VERSION ""

NS_ :

BS_:

BU_: CANOE_GW TARGET_IVI

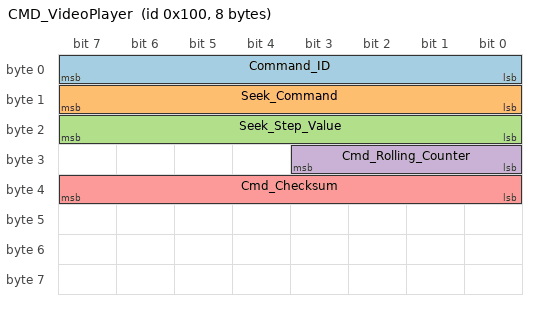
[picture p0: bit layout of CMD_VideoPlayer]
BO_ 256 CMD_VideoPlayer: 8 CANOE_GW
 SG_ Command_ID : 0|8@1+ (1,0) [0|4] "" TARGET_IVI
 SG_ Seek_Command : 8|8@1+ (1,0) [0|6] "" TARGET_IVI
 SG_ Seek_Step_Value : 16|8@1+ (1,0) [0|60] "s" TARGET_IVI
 SG_ Cmd_Rolling_Counter : 24|4@1+ (1,0) [0|15] "" TARGET_IVI
 SG_ Cmd_Checksum : 32|8@1+ (1,0) [0|255] "" TARGET_IVI

BO_ 257 STAT_VideoPlayer: 8 TARGET_IVI
 SG_ Playback_State : 0|8@1+ (1,0) [0|3] "" CANOE_GW
 SG_ Current_Track_Index : 8|8@1+ (1,0) [0|255] "" CANOE_GW
 SG_ Current_Play_Time : 16|16@0+ (1,0) [0|65535] "s" CANOE_GW
 SG_ Total_Duration : 32|16@0+ (1,0) [0|65535] "s" CANOE_GW
 SG_ System_Health_Status : 48|8@1+ (1,0) [0|255] "" CANOE_GW
 SG_ Status_Alive_Counter : 56|8@1+ (1,0) [0|255] "" CANOE_GW

VAL_ 256 Command_ID 0 "Idle" 1 "Play" 2 "Pause" 3 "Next" 4 "Previous" ;
VAL_ 256 Seek_Command 0 "None" 5 "Fast_Forward" 6 "Fast_Backward" ;
VAL_ 257 Playback_State 0 "Stopped" 1 "Playing" 2 "Paused" 3 "Error" ;
